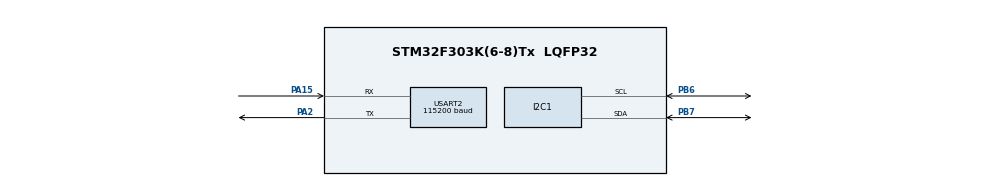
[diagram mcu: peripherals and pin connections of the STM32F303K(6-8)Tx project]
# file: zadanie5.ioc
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I2C1.I2C_Fall_Time=0
I2C1.I2C_Rise_Time=0
I2C1.OwnAddress=1
Mcu.Family=STM32F3
Mcu.Name=STM32F303K(6-8)Tx
Mcu.Package=LQFP32
NVIC.I2C1_EV_IRQn=true\:0\:0\:false\:false\:true\:true\:true\:true
NVIC.PriorityGroup=NVIC_PRIORITYGROUP_4
PA15.Mode=Asynchronous
PA15.Signal=USART2_RX
PA2.Mode=Asynchronous
PA2.Signal=USART2_TX
PB6.Mode=I2C
PB6.Signal=I2C1_SCL
PB7.Mode=I2C
PB7.Signal=I2C1_SDA
ProjectManager.HeapSize=0x200
ProjectManager.StackSize=0x400
ProjectManager.TargetToolchain=STM32CubeIDE
RCC.AHBFreq_Value=8000000
RCC.APB1Freq_Value=8000000
RCC.APB2Freq_Value=8000000
RCC.CortexFreq_Value=8000000
RCC.HSE_VALUE=8000000
RCC.HSI_VALUE=8000000
RCC.SYSCLKFreq_VALUE=8000000
USART2.BaudRate=115200
USART2.VirtualMode-Asynchronous=VM_ASYNC
board=custom

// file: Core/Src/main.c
/* USER CODE BEGIN Header */
/**
  ******************************************************************************
  * @file           : main.c
  * @brief          : Main program body
  ******************************************************************************
  * @attention
  *
  * Copyright (c) 2024 STMicroelectronics.
  * All rights reserved.
  *
  * This software is licensed under terms that can be found in the LICENSE file
  * in the root directory of this software component.
  * If no LICENSE file comes with this software, it is provided AS-IS.
  *
  ******************************************************************************
  */
/* USER CODE END Header */
#include "main.h"
#include "i2c.h"
#include "usart.h"
#include "gpio.h"
#include "lps25hb.h"
#include "hts221.h"
#include <stdio.h>

void SystemClock_Config(void);

int main(void)
{
	float pressure, altitude, humidity, temperature;
	char message[150];

	/* MCU Configuration--------------------------------------------------------*/

	/* Reset of all peripherals, Initializes the Flash interface and the Systick. */
	LL_APB2_GRP1_EnableClock(LL_APB2_GRP1_PERIPH_SYSCFG);
	LL_APB1_GRP1_EnableClock(LL_APB1_GRP1_PERIPH_PWR);

	/* System interrupt init*/
	NVIC_SetPriorityGrouping(NVIC_PRIORITYGROUP_4);

	/* SysTick_IRQn interrupt configuration */
	NVIC_SetPriority(SysTick_IRQn, NVIC_EncodePriority(NVIC_GetPriorityGrouping(),15, 0));

	/* Configure the system clock */
	SystemClock_Config();

	/* Initialize all configured peripherals */
	MX_GPIO_Init();
	MX_I2C1_Init();
	MX_USART2_UART_Init();
	/* USER CODE BEGIN 2 */
	LPS25HB_Init();
	HTS221_Init();
	/* USER CODE END 2 */

	/* Infinite loop */

	while (1)
	{
		/* USER CODE BEGIN WHILE */
		LPS25HB_ReadPressure(&pressure);
		altitude = LPS25HB_CalculateAltitude(pressure);

		humidity = HTS221_ReadHumidity();
		temperature = HTS221_ReadTemperature();
		sprintf(message, "Pressure: %.2f hPa, Altitude: %.2f m, Humidity: %.2f %%, Temperature: %.2f °C\r\n",
				pressure, altitude, humidity, temperature);
		USART2_SendString(message);

		LL_mDelay(200);
		/* USER CODE END WHILE */
	}

}

void SystemClock_Config(void)
{
  LL_FLASH_SetLatency(LL_FLASH_LATENCY_0);
  while(LL_FLASH_GetLatency()!= LL_FLASH_LATENCY_0)
  {
  }
  LL_RCC_HSI_Enable();

   /* Wait till HSI is ready */
  while(LL_RCC_HSI_IsReady() != 1)
  {

  }
  LL_RCC_HSI_SetCalibTrimming(16);
  LL_RCC_SetAHBPrescaler(LL_RCC_SYSCLK_DIV_1);
  LL_RCC_SetAPB1Prescaler(LL_RCC_APB1_DIV_1);
  LL_RCC_SetAPB2Prescaler(LL_RCC_APB2_DIV_1);
  LL_RCC_SetSysClkSource(LL_RCC_SYS_CLKSOURCE_HSI);

   /* Wait till System clock is ready */
  while(LL_RCC_GetSysClkSource() != LL_RCC_SYS_CLKSOURCE_STATUS_HSI)
  {

  }
  LL_Init1msTick(8000000);
  LL_SetSystemCoreClock(8000000);
  LL_RCC_SetI2CClockSource(LL_RCC_I2C1_CLKSOURCE_HSI);
}

void Error_Handler(void)
{
  __disable_irq();
  while (1)
  {
  }
}
